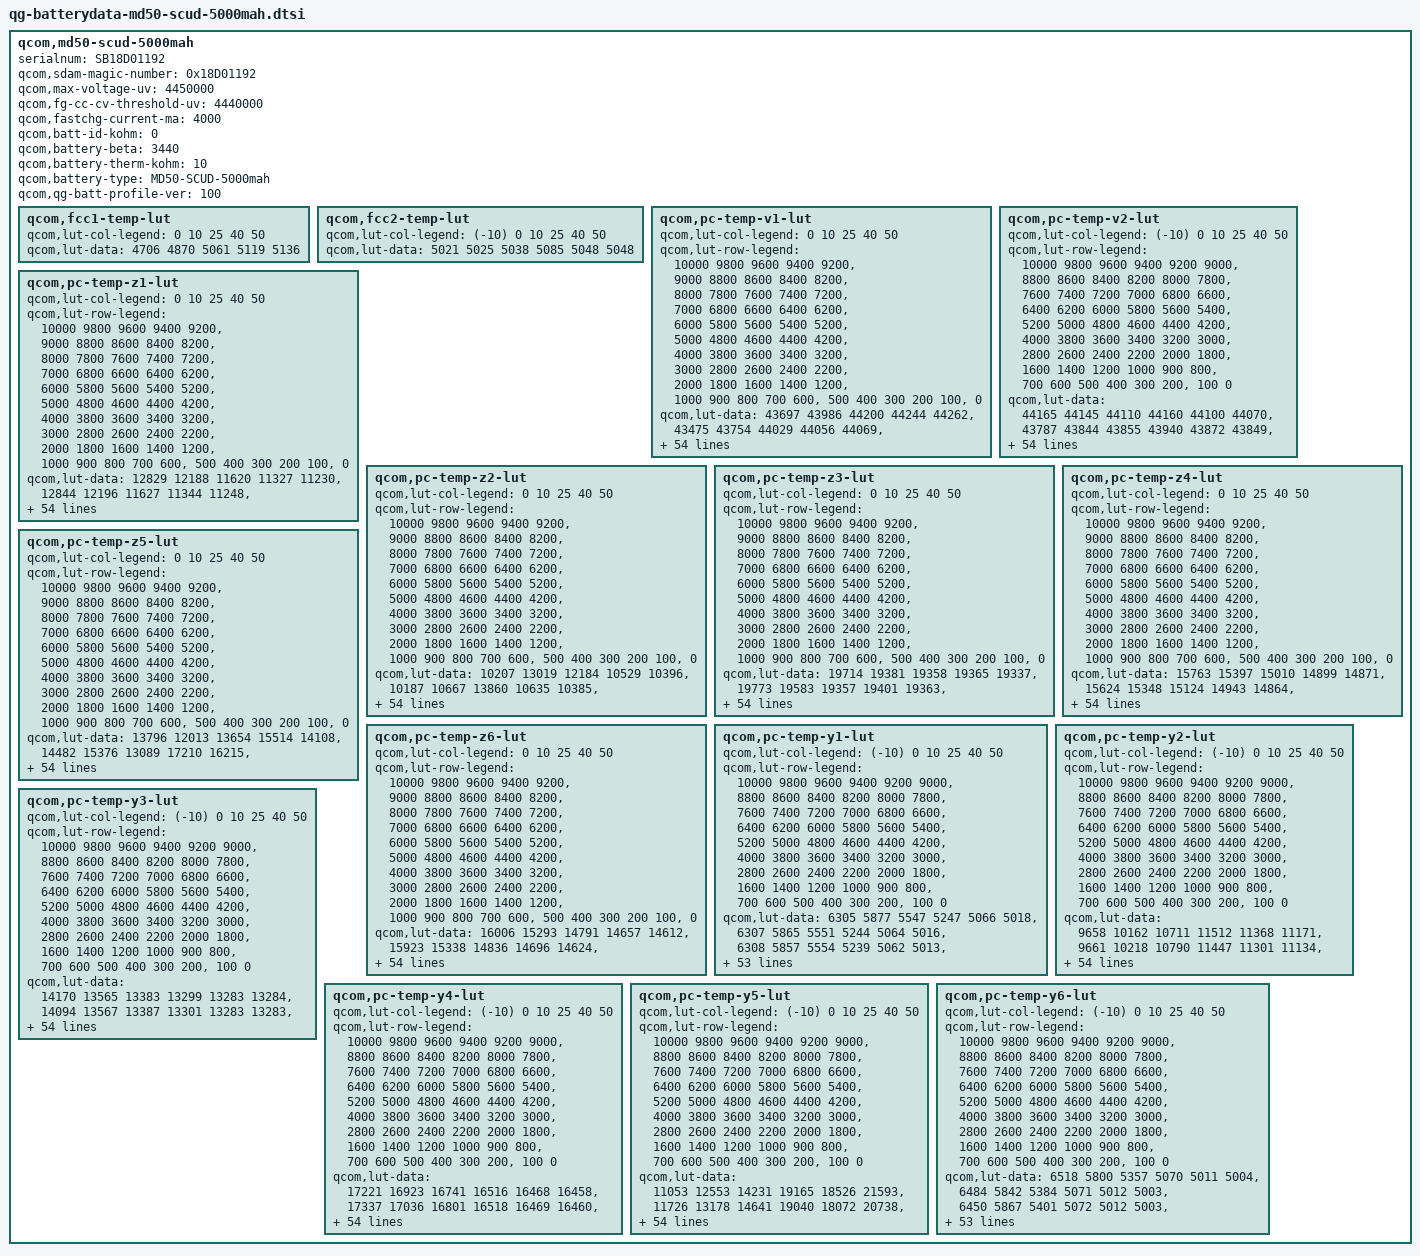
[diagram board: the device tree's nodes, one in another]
qcom,md50-scud-5000mah {
    /* 5012248_Lenovo_Denver_5000mAH_PM7250B_averaged_MasterSlave_Jan4th2021 */
    serialnum = "SB18D01192";
    qcom,sdam-magic-number = <0x18D01192>;
    qcom,max-voltage-uv = <4450000>;
    qcom,fg-cc-cv-threshold-uv = <4440000>;
    qcom,fastchg-current-ma = <4000>;
    qcom,batt-id-kohm = <0>;
    qcom,battery-beta = <3440>;
    qcom,battery-therm-kohm = <10>;
    qcom,battery-type = "MD50-SCUD-5000mah";
    qcom,qg-batt-profile-ver = <100>;

	qcom,fcc1-temp-lut {
		qcom,lut-col-legend = <0 10 25 40 50>;
		qcom,lut-data = <4706 4870 5061 5119 5136>;
	};

	qcom,fcc2-temp-lut {
		qcom,lut-col-legend = <(-10) 0 10 25 40 50>;
		qcom,lut-data = <5021 5025 5038 5085 5048 5048>;
	};

	qcom,pc-temp-v1-lut {
		qcom,lut-col-legend = <0 10 25 40 50>;
		qcom,lut-row-legend = <10000 9800 9600 9400 9200>,
			<9000 8800 8600 8400 8200>,
			<8000 7800 7600 7400 7200>,
			<7000 6800 6600 6400 6200>,
			<6000 5800 5600 5400 5200>,
			<5000 4800 4600 4400 4200>,
			<4000 3800 3600 3400 3200>,
			<3000 2800 2600 2400 2200>,
			<2000 1800 1600 1400 1200>,
			<1000 900 800 700 600>,
			<500 400 300 200 100>,
			<0>;
		qcom,lut-data = <43697 43986 44200 44244 44262>,
			<43475 43754 44029 44056 44069>,
			<43251 43531 43824 43871 43877>,
			<43024 43314 43608 43687 43687>,
			<42795 43092 43389 43484 43487>,
			<42567 42859 43163 43255 43272>,
			<42337 42625 42931 43019 43047>,
			<42111 42392 42691 42781 42815>,
			<41890 42161 42449 42540 42576>,
			<41676 41934 42208 42301 42337>,
			<41465 41710 41970 42067 42099>,
			<41258 41491 41737 41832 41862>,
			<41055 41279 41510 41595 41627>,
			<40852 41077 41290 41361 41394>,
			<40640 40876 41081 41138 41168>,
			<40432 40667 40877 40923 40948>,
			<40241 40457 40667 40716 40736>,
			<40064 40263 40451 40516 40535>,
			<39896 40083 40248 40322 40341>,
			<39738 39907 40076 40135 40152>,
			<39587 39732 39903 39954 39970>,
			<39435 39559 39669 39737 39762>,
			<39279 39366 39367 39440 39483>,
			<39123 39112 39128 39170 39216>,
			<38975 38879 38970 39010 39047>,
			<38829 38756 38845 38890 38920>,
			<38707 38675 38741 38780 38803>,
			<38620 38607 38655 38678 38696>,
			<38550 38542 38573 38585 38596>,
			<38491 38483 38492 38494 38501>,
			<38442 38428 38418 38409 38412>,
			<38399 38376 38350 38331 38327>,
			<38359 38327 38288 38259 38246>,
			<38324 38283 38228 38189 38168>,
			<38289 38243 38171 38118 38093>,
			<38254 38202 38117 38050 38020>,
			<38218 38162 38068 37988 37951>,
			<38173 38116 38023 37933 37887>,
			<38112 38046 37961 37865 37811>,
			<38036 37951 37866 37770 37709>,
			<37941 37844 37754 37658 37593>,
			<37816 37716 37635 37540 37470>,
			<37669 37572 37500 37408 37336>,
			<37497 37400 37334 37248 37177>,
			<37339 37261 37183 37103 37037>,
			<37242 37183 37094 37013 36955>,
			<37204 37160 37069 36993 36930>,
			<37174 37130 37054 36976 36915>,
			<37145 37101 37034 36961 36897>,
			<37087 37055 36996 36918 36846>,
			<36887 36857 36794 36692 36604>,
			<36428 36405 36361 36257 36167>,
			<35841 35818 35781 35678 35589>,
			<35046 35020 34990 34888 34805>,
			<33784 33769 33762 33667 33582>,
			<30000 30000 30000 30000 30000>;
	};

	qcom,pc-temp-v2-lut {
		qcom,lut-col-legend = <(-10) 0 10 25 40 50>;
		qcom,lut-row-legend = <10000 9800 9600 9400 9200 9000>,
			<8800 8600 8400 8200 8000 7800>,
			<7600 7400 7200 7000 6800 6600>,
			<6400 6200 6000 5800 5600 5400>,
			<5200 5000 4800 4600 4400 4200>,
			<4000 3800 3600 3400 3200 3000>,
			<2800 2600 2400 2200 2000 1800>,
			<1600 1400 1200 1000 900 800>,
			<700 600 500 400 300 200>,
			<100 0>;
		qcom,lut-data = <44165 44145 44110 44160 44100 44070>,
			<43787 43844 43855 43940 43872 43849>,
			<43441 43561 43606 43721 43647 43629>,
			<43133 43297 43366 43504 43427 43413>,
			<42857 43055 43135 43290 43212 43199>,
			<42595 42810 42899 43070 42992 42980>,
			<42339 42544 42652 42835 42760 42750>,
			<42090 42276 42401 42594 42522 42514>,
			<41833 42033 42154 42354 42286 42279>,
			<41562 41811 41910 42112 42047 42041>,
			<41347 41583 41670 41875 41812 41807>,
			<41221 41331 41428 41641 41579 41575>,
			<41110 41081 41193 41412 41351 41347>,
			<40918 40878 40976 41186 41128 41123>,
			<40610 40711 40773 40963 40910 40904>,
			<40288 40529 40574 40748 40698 40693>,
			<39974 40301 40378 40540 40492 40489>,
			<39670 40051 40179 40337 40291 40291>,
			<39412 39804 39961 40141 40102 40103>,
			<39187 39555 39724 39949 39923 39923>,
			<38981 39311 39489 39732 39721 39720>,
			<38773 39071 39251 39473 39463 39467>,
			<38592 38840 39026 39226 39208 39216>,
			<38470 38622 38842 39029 39016 39025>,
			<38380 38407 38682 38856 38855 38864>,
			<38303 38263 38536 38709 38716 38723>,
			<38235 38184 38402 38584 38593 38599>,
			<38172 38125 38279 38473 38485 38488>,
			<38109 38068 38157 38370 38384 38386>,
			<38046 38017 38041 38274 38290 38290>,
			<37986 37969 37961 38185 38204 38202>,
			<37928 37924 37912 38101 38126 38121>,
			<37871 37880 37872 38024 38051 38043>,
			<37811 37833 37825 37955 37974 37965>,
			<37750 37785 37779 37889 37897 37886>,
			<37687 37733 37730 37819 37811 37793>,
			<37621 37677 37680 37745 37713 37674>,
			<37551 37616 37624 37667 37613 37555>,
			<37471 37542 37551 37583 37519 37456>,
			<37381 37455 37463 37494 37428 37364>,
			<37287 37356 37361 37401 37331 37266>,
			<37187 37241 37240 37298 37229 37164>,
			<37087 37112 37108 37165 37104 37039>,
			<36994 36967 36970 37018 36957 36892>,
			<36915 36843 36848 36902 36856 36800>,
			<36833 36765 36749 36859 36827 36774>,
			<36787 36734 36706 36846 36818 36763>,
			<36737 36705 36660 36830 36803 36747>,
			<36669 36661 36602 36799 36776 36713>,
			<36555 36578 36506 36717 36683 36583>,
			<36319 36350 36276 36436 36346 36200>,
			<35898 35887 35827 35931 35833 35670>,
			<35268 35226 35186 35266 35161 34970>,
			<34356 34290 34281 34338 34209 33967>,
			<32823 32751 32749 32980 32675 32489>,
			<28965 28440 27863 27737 28090 28589>;
	};

	qcom,pc-temp-z1-lut {
		qcom,lut-col-legend = <0 10 25 40 50>;
		qcom,lut-row-legend = <10000 9800 9600 9400 9200>,
			<9000 8800 8600 8400 8200>,
			<8000 7800 7600 7400 7200>,
			<7000 6800 6600 6400 6200>,
			<6000 5800 5600 5400 5200>,
			<5000 4800 4600 4400 4200>,
			<4000 3800 3600 3400 3200>,
			<3000 2800 2600 2400 2200>,
			<2000 1800 1600 1400 1200>,
			<1000 900 800 700 600>,
			<500 400 300 200 100>,
			<0>;
		qcom,lut-data = <12829 12188 11620 11327 11230>,
			<12844 12196 11627 11344 11248>,
			<12852 12203 11637 11344 11248>,
			<12852 12212 11645 11342 11248>,
			<12851 12216 11639 11339 11247>,
			<12847 12215 11625 11333 11244>,
			<12827 12212 11616 11327 11240>,
			<12803 12206 11610 11322 11237>,
			<12794 12194 11604 11318 11235>,
			<12796 12180 11593 11314 11235>,
			<12796 12157 11581 11312 11236>,
			<12779 12134 11577 11310 11237>,
			<12745 12128 11575 11308 11236>,
			<12723 12128 11573 11307 11236>,
			<12713 12128 11570 11307 11235>,
			<12706 12122 11566 11307 11234>,
			<12701 12111 11563 11307 11234>,
			<12689 12102 11560 11305 11234>,
			<12679 12092 11559 11304 11235>,
			<12675 12086 11560 11305 11235>,
			<12672 12090 11562 11305 11236>,
			<12666 12101 11563 11306 11237>,
			<12654 12105 11564 11305 11236>,
			<12639 12099 11564 11305 11236>,
			<12631 12092 11567 11306 11236>,
			<12623 12092 11570 11308 11236>,
			<12616 12094 11570 11309 11237>,
			<12610 12096 11571 11311 11239>,
			<12604 12099 11572 11313 11242>,
			<12601 12103 11576 11317 11245>,
			<12599 12104 11581 11321 11248>,
			<12597 12105 11585 11326 11252>,
			<12598 12106 11589 11330 11256>,
			<12603 12108 11593 11334 11260>,
			<12608 12109 11598 11340 11264>,
			<12616 12113 11604 11346 11269>,
			<12632 12123 11607 11350 11272>,
			<12639 12134 11610 11353 11275>,
			<12651 12143 11616 11356 11278>,
			<12668 12153 11627 11359 11281>,
			<12685 12162 11637 11362 11284>,
			<12715 12170 11643 11366 11286>,
			<12745 12184 11647 11371 11288>,
			<12771 12216 11648 11376 11290>,
			<12725 12210 11654 11381 11294>,
			<12736 12203 11663 11386 11297>,
			<12719 12199 11662 11388 11297>,
			<12716 12213 11664 11386 11298>,
			<12734 12198 11652 11390 11301>,
			<12727 12214 11669 11392 11304>,
			<12754 12225 11669 11398 11308>,
			<12777 12240 11685 11404 11313>,
			<12760 12232 11692 11414 11322>,
			<12800 12271 11710 11427 11335>,
			<12800 12271 11710 11427 11335>,
			<12800 12271 11710 11427 11335>;
	};

	qcom,pc-temp-z2-lut {
		qcom,lut-col-legend = <0 10 25 40 50>;
		qcom,lut-row-legend = <10000 9800 9600 9400 9200>,
			<9000 8800 8600 8400 8200>,
			<8000 7800 7600 7400 7200>,
			<7000 6800 6600 6400 6200>,
			<6000 5800 5600 5400 5200>,
			<5000 4800 4600 4400 4200>,
			<4000 3800 3600 3400 3200>,
			<3000 2800 2600 2400 2200>,
			<2000 1800 1600 1400 1200>,
			<1000 900 800 700 600>,
			<500 400 300 200 100>,
			<0>;
		qcom,lut-data = <10207 13019 12184 10529 10396>,
			<10187 10667 13860 10635 10385>,
			<10166 10426 12145 11080 10591>,
			<10143 10400 10677 11779 10582>,
			<10118 10375 10577 11902 10568>,
			<10098 10340 10538 11158 10525>,
			<10080 10308 10504 10529 10469>,
			<10066 10286 10471 10460 10430>,
			<10062 10270 10444 10425 10396>,
			<10061 10258 10418 10503 10361>,
			<10061 10249 10398 10976 10314>,
			<10062 10243 10395 11274 10286>,
			<10064 10243 10400 10942 10305>,
			<10065 10252 10411 10472 10344>,
			<10059 10262 10656 10506 10364>,
			<10050 10272 11016 10880 10378>,
			<10051 10284 11011 11069 10383>,
			<10065 10301 10704 11337 10338>,
			<10083 10332 10528 11639 10278>,
			<10101 10361 10540 11433 10293>,
			<10121 10378 10564 10805 10399>,
			<10141 10392 10600 10579 10511>,
			<10160 10398 10659 10674 10651>,
			<10180 10400 10684 10761 10758>,
			<10199 10401 10643 10693 10674>,
			<10219 10401 10595 10539 10438>,
			<10239 10401 10593 10501 10360>,
			<10259 10401 10605 10530 10394>,
			<10280 10407 10615 10560 10428>,
			<10297 10417 10630 10599 10436>,
			<10309 10428 10643 10649 10442>,
			<10320 10441 10642 10658 10469>,
			<10334 10454 10639 10658 10568>,
			<10348 10464 10638 10658 10631>,
			<10363 10473 10649 10658 10619>,
			<10380 10484 10665 10660 10601>,
			<10398 10494 10678 10679 10604>,
			<10407 10507 10692 10735 10637>,
			<10368 10525 10714 10787 10680>,
			<10310 10549 10755 10835 10755>,
			<10248 10572 10792 10867 10822>,
			<10112 10592 10805 10867 10833>,
			<10026 10623 10815 10863 10829>,
			<9965 10688 10838 10866 10817>,
			<9722 11016 10982 10900 10763>,
			<9516 10899 11105 10940 10682>,
			<9514 10691 11085 10786 10650>,
			<9515 10650 11063 10764 10653>,
			<9517 10661 11055 10803 10696>,
			<9536 10595 11122 10948 10852>,
			<9556 10635 11231 10880 10707>,
			<9436 10499 11215 10715 10423>,
			<9384 10361 11129 10585 10333>,
			<9344 10237 11079 10469 10292>,
			<9344 10237 11079 10469 10292>,
			<9344 10237 11079 10469 10292>;
	};

	qcom,pc-temp-z3-lut {
		qcom,lut-col-legend = <0 10 25 40 50>;
		qcom,lut-row-legend = <10000 9800 9600 9400 9200>,
			<9000 8800 8600 8400 8200>,
			<8000 7800 7600 7400 7200>,
			<7000 6800 6600 6400 6200>,
			<6000 5800 5600 5400 5200>,
			<5000 4800 4600 4400 4200>,
			<4000 3800 3600 3400 3200>,
			<3000 2800 2600 2400 2200>,
			<2000 1800 1600 1400 1200>,
			<1000 900 800 700 600>,
			<500 400 300 200 100>,
			<0>;
		qcom,lut-data = <19714 19381 19358 19365 19337>,
			<19773 19583 19357 19401 19363>,
			<19811 19626 19428 19417 19396>,
			<19822 19643 19484 19424 19404>,
			<19828 19649 19494 19431 19409>,
			<19833 19651 19500 19440 19416>,
			<19840 19651 19501 19446 19421>,
			<19846 19649 19500 19446 19421>,
			<19845 19644 19498 19446 19421>,
			<19830 19640 19496 19449 19420>,
			<19813 19638 19493 19468 19415>,
			<19806 19634 19486 19479 19409>,
			<19799 19630 19471 19456 19405>,
			<19798 19624 19463 19421 19400>,
			<19813 19618 19476 19413 19396>,
			<19833 19616 19497 19417 19392>,
			<19837 19613 19494 19420 19388>,
			<19834 19611 19462 19422 19377>,
			<19831 19605 19442 19422 19367>,
			<19831 19602 19438 19411 19366>,
			<19830 19603 19437 19391 19366>,
			<19830 19608 19442 19385 19367>,
			<19834 19614 19464 19396 19375>,
			<19839 19625 19475 19407 19382>,
			<19839 19634 19467 19400 19376>,
			<19836 19633 19455 19384 19360>,
			<19830 19624 19447 19375 19351>,
			<19820 19616 19440 19371 19347>,
			<19805 19608 19438 19369 19345>,
			<19791 19600 19440 19369 19346>,
			<19779 19596 19442 19371 19349>,
			<19767 19595 19444 19375 19354>,
			<19756 19593 19446 19381 19370>,
			<19745 19590 19448 19386 19379>,
			<19735 19586 19449 19389 19377>,
			<19726 19583 19450 19392 19373>,
			<19717 19580 19447 19391 19369>,
			<19701 19577 19441 19384 19364>,
			<19623 19573 19437 19380 19360>,
			<19538 19566 19435 19378 19357>,
			<19490 19559 19434 19376 19356>,
			<19388 19552 19429 19374 19357>,
			<19357 19543 19423 19371 19362>,
			<19347 19527 19418 19369 19362>,
			<19314 19468 19404 19364 19360>,
			<19285 19377 19384 19355 19341>,
			<19284 19311 19384 19345 19338>,
			<19284 19304 19379 19343 19330>,
			<19282 19299 19377 19336 19326>,
			<19276 19296 19372 19326 19319>,
			<19274 19301 19364 19336 19337>,
			<19287 19301 19365 19367 19361>,
			<19291 19301 19366 19367 19363>,
			<19296 19301 19336 19362 19351>,
			<19296 19301 19336 19362 19351>,
			<19296 19301 19336 19362 19351>;
	};

	qcom,pc-temp-z4-lut {
		qcom,lut-col-legend = <0 10 25 40 50>;
		qcom,lut-row-legend = <10000 9800 9600 9400 9200>,
			<9000 8800 8600 8400 8200>,
			<8000 7800 7600 7400 7200>,
			<7000 6800 6600 6400 6200>,
			<6000 5800 5600 5400 5200>,
			<5000 4800 4600 4400 4200>,
			<4000 3800 3600 3400 3200>,
			<3000 2800 2600 2400 2200>,
			<2000 1800 1600 1400 1200>,
			<1000 900 800 700 600>,
			<500 400 300 200 100>,
			<0>;
		qcom,lut-data = <15763 15397 15010 14899 14871>,
			<15624 15348 15124 14943 14864>,
			<15501 15271 15070 14940 14898>,
			<15395 15166 15003 14873 14867>,
			<15301 15079 14952 14835 14838>,
			<15220 15015 14905 14820 14814>,
			<15147 14962 14866 14806 14792>,
			<15086 14920 14833 14788 14773>,
			<15047 14887 14805 14767 14756>,
			<15020 14859 14780 14735 14741>,
			<14998 14835 14759 14680 14729>,
			<14974 14814 14745 14650 14717>,
			<14952 14796 14737 14668 14707>,
			<14929 14779 14727 14693 14697>,
			<14899 14764 14688 14690 14690>,
			<14871 14753 14641 14666 14683>,
			<14853 14744 14642 14652 14680>,
			<14841 14736 14678 14639 14679>,
			<14829 14729 14698 14624 14679>,
			<14813 14724 14694 14630 14677>,
			<14797 14722 14689 14650 14672>,
			<14786 14722 14700 14678 14671>,
			<14779 14723 14744 14728 14712>,
			<14775 14761 14777 14771 14764>,
			<14776 14804 14795 14788 14784>,
			<14785 14808 14806 14799 14798>,
			<14792 14801 14804 14800 14800>,
			<14790 14793 14795 14792 14793>,
			<14784 14784 14784 14782 14782>,
			<14777 14774 14769 14768 14769>,
			<14770 14763 14753 14752 14753>,
			<14763 14750 14737 14734 14732>,
			<14756 14738 14721 14713 14701>,
			<14748 14729 14710 14696 14681>,
			<14741 14720 14700 14685 14677>,
			<14733 14714 14694 14678 14675>,
			<14725 14707 14693 14677 14674>,
			<14725 14704 14693 14678 14675>,
			<14797 14705 14693 14679 14676>,
			<14877 14706 14700 14688 14686>,
			<14918 14707 14706 14697 14697>,
			<15018 14702 14704 14698 14694>,
			<15031 14697 14701 14696 14686>,
			<15000 14692 14698 14696 14686>,
			<14914 14680 14683 14688 14682>,
			<14925 14740 14663 14665 14669>,
			<14922 14806 14656 14666 14666>,
			<14917 14810 14647 14655 14658>,
			<14914 14810 14638 14645 14641>,
			<14912 14811 14640 14646 14639>,
			<14910 14807 14661 14662 14652>,
			<14919 14818 14674 14647 14646>,
			<14926 14822 14675 14651 14649>,
			<14939 14829 14712 14661 14664>,
			<14939 14829 14712 14661 14664>,
			<14939 14829 14712 14661 14664>;
	};

	qcom,pc-temp-z5-lut {
		qcom,lut-col-legend = <0 10 25 40 50>;
		qcom,lut-row-legend = <10000 9800 9600 9400 9200>,
			<9000 8800 8600 8400 8200>,
			<8000 7800 7600 7400 7200>,
			<7000 6800 6600 6400 6200>,
			<6000 5800 5600 5400 5200>,
			<5000 4800 4600 4400 4200>,
			<4000 3800 3600 3400 3200>,
			<3000 2800 2600 2400 2200>,
			<2000 1800 1600 1400 1200>,
			<1000 900 800 700 600>,
			<500 400 300 200 100>,
			<0>;
		qcom,lut-data = <13796 12013 13654 15514 14108>,
			<14482 15376 13089 17210 16215>,
			<15001 16499 15171 17301 17998>,
			<15297 17055 17070 17262 18462>,
			<15494 17504 17650 17379 18850>,
			<15744 17966 18014 18612 19420>,
			<16255 18361 18438 19944 20012>,
			<16758 18680 18915 20493 20512>,
			<16832 19056 19457 20949 20957>,
			<16658 19458 20300 23276 21171>,
			<16512 19985 21154 32246 21167>,
			<16537 20642 21280 37725 21308>,
			<16659 21255 21077 32499 22043>,
			<16872 21818 20956 24892 23220>,
			<18037 22507 30023 26046 24316>,
			<19763 23554 43712 35857 25512>,
			<20954 24947 43534 40727 26078>,
			<21761 26424 31786 44638 25072>,
			<22717 27891 25038 48166 23662>,
			<24227 29771 25476 43256 24111>,
			<26411 32914 26612 33557 27059>,
			<29390 37728 33090 30766 30435>,
			<34956 43200 52809 39925 35306>,
			<41436 51205 62296 48302 39155>,
			<46239 57714 51612 42768 35733>,
			<50714 56062 36901 29574 25597>,
			<53118 47110 30609 23532 20540>,
			<52141 39969 26571 21127 18851>,
			<49519 36356 25164 20027 18018>,
			<47004 33940 25054 19862 17838>,
			<44484 33738 25188 19823 17778>,
			<42292 34753 25938 20164 18456>,
			<41029 36114 27943 21926 22683>,
			<39611 37611 30643 24417 26708>,
			<38809 39430 35833 29422 29117>,
			<38621 41416 39856 34360 30817>,
			<38264 44028 39743 34833 30946>,
			<37865 45851 38903 34393 30535>,
			<33367 46085 38275 33729 29907>,
			<28379 46015 37656 32353 28313>,
			<24691 45670 36725 30408 26636>,
			<14537 44216 34202 27659 25995>,
			<12224 42622 31267 24895 25609>,
			<12276 41505 30531 24678 25837>,
			<12637 35568 32418 25152 25910>,
			<12081 21047 31790 26051 22104>,
			<12063 13245 32729 22695 21084>,
			<12035 12981 31772 23743 20137>,
			<11993 12841 32869 23256 22408>,
			<11987 12771 30841 21204 21240>,
			<12045 13022 23772 20824 23156>,
			<12096 12885 20340 25746 26258>,
			<12016 12731 19676 24135 24359>,
			<11913 12556 15240 20338 18409>,
			<11913 12556 15240 20338 18409>,
			<11913 12556 15240 20338 18409>;
	};

	qcom,pc-temp-z6-lut {
		qcom,lut-col-legend = <0 10 25 40 50>;
		qcom,lut-row-legend = <10000 9800 9600 9400 9200>,
			<9000 8800 8600 8400 8200>,
			<8000 7800 7600 7400 7200>,
			<7000 6800 6600 6400 6200>,
			<6000 5800 5600 5400 5200>,
			<5000 4800 4600 4400 4200>,
			<4000 3800 3600 3400 3200>,
			<3000 2800 2600 2400 2200>,
			<2000 1800 1600 1400 1200>,
			<1000 900 800 700 600>,
			<500 400 300 200 100>,
			<0>;
		qcom,lut-data = <16006 15293 14791 14657 14612>,
			<15923 15338 14836 14696 14624>,
			<15844 15321 14838 14701 14654>,
			<15769 15255 14838 14680 14646>,
			<15696 15194 14827 14668 14639>,
			<15634 15150 14800 14663 14632>,
			<15582 15110 14778 14658 14625>,
			<15536 15077 14760 14650 14618>,
			<15496 15048 14744 14640 14610>,
			<15460 15023 14729 14630 14603>,
			<15428 15003 14716 14620 14596>,
			<15400 14984 14703 14610 14588>,
			<15374 14967 14692 14602 14581>,
			<15353 14949 14682 14595 14574>,
			<15337 14934 14672 14588 14568>,
			<15324 14923 14663 14581 14563>,
			<15310 14913 14658 14575 14558>,
			<15297 14905 14655 14569 14552>,
			<15284 14898 14653 14564 14546>,
			<15272 14893 14649 14562 14543>,
			<15260 14894 14647 14561 14542>,
			<15252 14897 14655 14563 14542>,
			<15248 14902 14687 14591 14565>,
			<15246 14925 14704 14617 14590>,
			<15243 14948 14706 14617 14592>,
			<15241 14949 14707 14615 14590>,
			<15238 14943 14705 14613 14588>,
			<15231 14936 14698 14608 14584>,
			<15219 14929 14692 14602 14579>,
			<15208 14922 14687 14597 14574>,
			<15198 14916 14682 14592 14569>,
			<15189 14910 14678 14587 14564>,
			<15181 14906 14673 14582 14560>,
			<15174 14901 14670 14579 14557>,
			<15168 14898 14668 14577 14554>,
			<15162 14896 14667 14576 14552>,
			<15158 14895 14665 14574 14549>,
			<15156 14894 14663 14571 14546>,
			<15156 14896 14663 14570 14545>,
			<15157 14899 14666 14573 14548>,
			<15157 14900 14669 14576 14552>,
			<15159 14900 14668 14576 14551>,
			<15157 14900 14666 14574 14551>,
			<15152 14897 14664 14574 14551>,
			<15111 14871 14655 14568 14548>,
			<15102 14855 14639 14555 14533>,
			<15101 14850 14636 14550 14530>,
			<15099 14849 14629 14544 14523>,
			<15100 14848 14625 14536 14514>,
			<15104 14850 14625 14532 14509>,
			<15113 14857 14633 14545 14524>,
			<15129 14869 14642 14557 14537>,
			<15146 14879 14647 14561 14542>,
			<15172 14895 14653 14566 14545>,
			<15172 14895 14653 14566 14545>,
			<15172 14895 14653 14566 14545>;
	};

	qcom,pc-temp-y1-lut {
		qcom,lut-col-legend = <(-10) 0 10 25 40 50>;
		qcom,lut-row-legend = <10000 9800 9600 9400 9200 9000>,
			<8800 8600 8400 8200 8000 7800>,
			<7600 7400 7200 7000 6800 6600>,
			<6400 6200 6000 5800 5600 5400>,
			<5200 5000 4800 4600 4400 4200>,
			<4000 3800 3600 3400 3200 3000>,
			<2800 2600 2400 2200 2000 1800>,
			<1600 1400 1200 1000 900 800>,
			<700 600 500 400 300 200>,
			<100 0>;
		qcom,lut-data = <6305 5877 5547 5247 5066 5018>,
			<6307 5865 5551 5244 5064 5016>,
			<6308 5857 5554 5239 5062 5013>,
			<6309 5852 5555 5235 5060 5010>,
			<6310 5850 5555 5231 5059 5007>,
			<6310 5850 5555 5229 5058 5005>,
			<6311 5853 5554 5227 5057 5002>,
			<6312 5859 5552 5226 5057 5000>,
			<6313 5861 5551 5224 5055 4998>,
			<6318 5862 5551 5221 5053 4996>,
			<6322 5863 5550 5219 5051 4995>,
			<6326 5865 5550 5218 5050 4994>,
			<6331 5868 5549 5217 5049 4992>,
			<6334 5869 5550 5216 5048 4991>,
			<6343 5870 5551 5215 5047 4990>,
			<6348 5871 5551 5214 5047 4990>,
			<6346 5871 5552 5213 5046 4990>,
			<6343 5871 5553 5212 5045 4989>,
			<6341 5872 5553 5213 5045 4990>,
			<6336 5875 5553 5216 5046 4990>,
			<6333 5877 5553 5217 5046 4990>,
			<6333 5878 5553 5216 5047 4990>,
			<6333 5878 5554 5216 5047 4990>,
			<6333 5878 5555 5218 5047 4990>,
			<6331 5876 5555 5220 5048 4991>,
			<6329 5873 5556 5221 5049 4992>,
			<6329 5871 5556 5222 5050 4993>,
			<6329 5869 5557 5223 5051 4993>,
			<6328 5868 5558 5225 5052 4994>,
			<6326 5868 5560 5227 5054 4997>,
			<6324 5867 5561 5229 5056 4998>,
			<6322 5866 5559 5231 5058 5000>,
			<6320 5864 5558 5233 5060 5002>,
			<6318 5861 5558 5235 5062 5003>,
			<6315 5856 5560 5237 5064 5004>,
			<6314 5854 5561 5239 5065 5005>,
			<6312 5854 5558 5240 5066 5007>,
			<6311 5854 5556 5241 5067 5008>,
			<6309 5851 5555 5242 5068 5009>,
			<6305 5846 5555 5242 5069 5009>,
			<6304 5844 5554 5243 5071 5010>,
			<6299 5845 5554 5244 5073 5011>,
			<6296 5846 5554 5247 5074 5012>,
			<6300 5843 5557 5250 5075 5015>,
			<6309 5850 5560 5253 5079 5018>,
			<6324 5868 5566 5256 5081 5020>,
			<6335 5870 5568 5258 5082 5020>,
			<6338 5875 5570 5258 5082 5020>,
			<6338 5874 5573 5259 5081 5021>,
			<6341 5871 5574 5262 5082 5022>,
			<6351 5870 5581 5261 5085 5024>,
			<6341 5876 5586 5267 5087 5029>,
			<6383 5892 5596 5279 5096 5035>,
			<6537 5924 5616 5294 5105 5044>,
			<6537 5924 5616 5294 5105 5044>,
			<6537 5924 5616 5294 5105 5044>;
	};

	qcom,pc-temp-y2-lut {
		qcom,lut-col-legend = <(-10) 0 10 25 40 50>;
		qcom,lut-row-legend = <10000 9800 9600 9400 9200 9000>,
			<8800 8600 8400 8200 8000 7800>,
			<7600 7400 7200 7000 6800 6600>,
			<6400 6200 6000 5800 5600 5400>,
			<5200 5000 4800 4600 4400 4200>,
			<4000 3800 3600 3400 3200 3000>,
			<2800 2600 2400 2200 2000 1800>,
			<1600 1400 1200 1000 900 800>,
			<700 600 500 400 300 200>,
			<100 0>;
		qcom,lut-data = <9658 10162 10711 11512 11368 11171>,
			<9661 10218 10790 11447 11301 11134>,
			<9664 10305 10851 11385 11219 11096>,
			<9668 10399 10893 11327 11138 11059>,
			<9670 10473 10917 11276 11073 11021>,
			<9672 10502 10925 11235 11040 10984>,
			<9674 10495 10905 11199 11032 10941>,
			<9676 10484 10876 11171 11031 10904>,
			<9676 10515 10867 11155 11033 10889>,
			<9676 10668 10864 11145 11041 10879>,
			<9675 10757 10863 11134 11045 10877>,
			<9677 10737 10870 11115 11042 10918>,
			<9680 10708 10887 11101 11041 10967>,
			<9680 10722 10925 11104 11053 10962>,
			<9680 10807 11015 11117 11079 10921>,
			<9679 10881 11090 11136 11103 10902>,
			<9676 10926 11135 11172 11117 10959>,
			<9673 10956 11170 11223 11134 11049>,
			<9671 10958 11201 11286 11179 11116>,
			<9670 10946 11231 11360 11267 11178>,
			<9669 10916 11242 11400 11333 11224>,
			<9668 10418 11235 11416 11375 11266>,
			<9667 9797 11225 11432 11404 11296>,
			<9667 9702 11218 11464 11413 11299>,
			<9666 9691 11213 11505 11417 11290>,
			<9665 9684 11204 11532 11424 11293>,
			<9665 9680 11170 11548 11449 11319>,
			<9665 9678 11128 11567 11478 11357>,
			<9665 9675 11102 11602 11539 11427>,
			<9664 9673 11080 11643 11658 11537>,
			<9664 9670 11051 11666 11718 11603>,
			<9663 9668 11003 11683 11755 11638>,
			<9663 9666 10925 11690 11781 11665>,
			<9663 9665 10694 11682 11787 11711>,
			<9663 9664 10251 11669 11790 11777>,
			<9663 9663 9987 11661 11775 11789>,
			<9663 9663 9863 11655 11708 11722>,
			<9662 9662 9785 11644 11646 11649>,
			<9662 9662 9741 11609 11622 11570>,
			<9662 9662 9711 11562 11606 11456>,
			<9662 9661 9694 11529 11606 11437>,
			<9662 9661 9684 11501 11626 11502>,
			<9662 9661 9676 11476 11625 11502>,
			<9661 9661 9671 11436 11572 11365>,
			<9661 9660 9667 11395 11401 11211>,
			<9660 9659 9666 11352 11322 11129>,
			<9660 9659 9665 11349 11316 11149>,
			<9659 9659 9664 11321 11312 11156>,
			<9659 9659 9662 11307 11318 11195>,
			<9658 9658 9661 11290 11341 11160>,
			<9657 9658 9660 11263 11285 11007>,
			<9656 9657 9659 11189 11182 10952>,
			<9654 9656 9658 11079 11102 10904>,
			<9652 9654 9657 10933 10975 10753>,
			<9652 9654 9657 10933 10975 10753>,
			<9652 9654 9657 10933 10975 10753>;
	};

	qcom,pc-temp-y3-lut {
		qcom,lut-col-legend = <(-10) 0 10 25 40 50>;
		qcom,lut-row-legend = <10000 9800 9600 9400 9200 9000>,
			<8800 8600 8400 8200 8000 7800>,
			<7600 7400 7200 7000 6800 6600>,
			<6400 6200 6000 5800 5600 5400>,
			<5200 5000 4800 4600 4400 4200>,
			<4000 3800 3600 3400 3200 3000>,
			<2800 2600 2400 2200 2000 1800>,
			<1600 1400 1200 1000 900 800>,
			<700 600 500 400 300 200>,
			<100 0>;
		qcom,lut-data = <14170 13565 13383 13299 13283 13284>,
			<14094 13567 13387 13301 13283 13283>,
			<14019 13567 13393 13303 13283 13282>,
			<13950 13566 13398 13305 13284 13282>,
			<13890 13565 13403 13307 13285 13282>,
			<13843 13563 13406 13308 13285 13282>,
			<13810 13558 13407 13308 13286 13283>,
			<13782 13552 13407 13308 13287 13284>,
			<13743 13554 13408 13308 13288 13285>,
			<13688 13566 13408 13308 13289 13286>,
			<13661 13572 13409 13309 13290 13287>,
			<13666 13529 13411 13311 13290 13288>,
			<13672 13470 13413 13314 13291 13288>,
			<13673 13462 13409 13314 13292 13288>,
			<13667 13469 13394 13313 13296 13288>,
			<13659 13473 13385 13312 13298 13288>,
			<13633 13466 13384 13313 13297 13290>,
			<13603 13452 13383 13314 13296 13293>,
			<13598 13438 13380 13314 13297 13294>,
			<13598 13420 13372 13314 13299 13295>,
			<13598 13412 13363 13313 13299 13295>,
			<13593 13422 13356 13309 13295 13291>,
			<13587 13434 13349 13305 13289 13286>,
			<13589 13428 13345 13301 13286 13283>,
			<13606 13401 13341 13298 13284 13281>,
			<13628 13388 13337 13296 13283 13281>,
			<13655 13398 13334 13294 13282 13280>,
			<13688 13416 13331 13294 13282 13280>,
			<13721 13438 13325 13294 13282 13280>,
			<13755 13468 13317 13296 13283 13280>,
			<13792 13501 13314 13296 13283 13280>,
			<13832 13541 13319 13295 13283 13280>,
			<13873 13583 13326 13295 13283 13279>,
			<13910 13625 13328 13295 13283 13280>,
			<13944 13668 13329 13295 13283 13281>,
			<13979 13710 13333 13295 13283 13281>,
			<14016 13752 13346 13295 13283 13280>,
			<14053 13794 13365 13295 13282 13279>,
			<14086 13837 13383 13294 13282 13279>,
			<14117 13880 13403 13293 13282 13279>,
			<14147 13920 13426 13294 13282 13280>,
			<14176 13956 13455 13296 13285 13282>,
			<14208 13993 13491 13295 13284 13282>,
			<14248 14037 13538 13294 13281 13278>,
			<14321 14087 13611 13296 13282 13281>,
			<14366 14107 13608 13297 13287 13286>,
			<14438 14162 13659 13301 13291 13290>,
			<14522 14222 13720 13307 13295 13292>,
			<14625 14289 13796 13312 13298 13294>,
			<14771 14365 13880 13315 13297 13291>,
			<14976 14459 13954 13312 13293 13287>,
			<15390 14622 14063 13312 13290 13288>,
			<16713 14895 14258 13319 13296 13295>,
			<20926 15613 14486 13331 13303 13301>,
			<20926 15613 14486 13331 13303 13301>,
			<20926 15613 14486 13331 13303 13301>;
	};

	qcom,pc-temp-y4-lut {
		qcom,lut-col-legend = <(-10) 0 10 25 40 50>;
		qcom,lut-row-legend = <10000 9800 9600 9400 9200 9000>,
			<8800 8600 8400 8200 8000 7800>,
			<7600 7400 7200 7000 6800 6600>,
			<6400 6200 6000 5800 5600 5400>,
			<5200 5000 4800 4600 4400 4200>,
			<4000 3800 3600 3400 3200 3000>,
			<2800 2600 2400 2200 2000 1800>,
			<1600 1400 1200 1000 900 800>,
			<700 600 500 400 300 200>,
			<100 0>;
		qcom,lut-data = <17221 16923 16741 16516 16468 16458>,
			<17337 17036 16801 16518 16469 16460>,
			<17442 17163 16862 16519 16470 16461>,
			<17528 17281 16917 16520 16471 16462>,
			<17586 17369 16957 16520 16471 16464>,
			<17607 17401 16971 16521 16472 16465>,
			<17580 17386 16961 16521 16473 16466>,
			<17540 17355 16943 16522 16474 16466>,
			<17534 17319 16930 16524 16475 16468>,
			<17541 17268 16920 16528 16478 16469>,
			<17550 17244 16910 16531 16482 16471>,
			<17576 17300 16897 16534 16487 16475>,
			<17606 17378 16887 16538 16492 16480>,
			<17579 17387 16901 16544 16496 16486>,
			<17428 17374 16963 16557 16499 16494>,
			<17276 17353 16996 16571 16504 16501>,
			<17171 17301 16997 16588 16514 16506>,
			<17078 17224 16995 16608 16530 16511>,
			<17001 17150 16980 16636 16549 16523>,
			<16936 17072 16929 16667 16573 16543>,
			<16882 16993 16870 16670 16581 16550>,
			<16829 16911 16802 16613 16547 16526>,
			<16791 16833 16738 16553 16504 16494>,
			<16788 16767 16702 16524 16486 16480>,
			<16793 16704 16678 16504 16474 16469>,
			<16796 16681 16654 16500 16471 16466>,
			<16795 16685 16629 16502 16475 16469>,
			<16795 16693 16604 16506 16480 16473>,
			<16797 16699 16578 16510 16487 16479>,
			<16805 16705 16551 16515 16495 16487>,
			<16811 16711 16542 16520 16505 16496>,
			<16814 16717 16551 16527 16518 16509>,
			<16818 16724 16568 16533 16528 16518>,
			<16822 16733 16595 16539 16528 16521>,
			<16828 16743 16637 16543 16528 16522>,
			<16831 16753 16669 16540 16526 16520>,
			<16834 16762 16691 16527 16507 16500>,
			<16835 16768 16708 16516 16490 16482>,
			<16833 16768 16720 16507 16484 16480>,
			<16827 16767 16729 16501 16481 16479>,
			<16820 16766 16730 16504 16481 16479>,
			<16813 16758 16723 16512 16483 16482>,
			<16810 16746 16721 16513 16482 16480>,
			<16822 16727 16723 16512 16471 16465>,
			<16825 16719 16732 16493 16461 16456>,
			<16818 16708 16728 16501 16471 16472>,
			<16834 16721 16769 16516 16488 16499>,
			<16855 16739 16813 16538 16518 16534>,
			<16883 16774 16870 16574 16556 16572>,
			<16902 16818 16937 16603 16570 16558>,
			<16901 16820 16965 16561 16486 16481>,
			<16906 16797 16963 16543 16480 16480>,
			<17120 16803 16976 16564 16488 16483>,
			<18668 16971 16989 16616 16513 16511>,
			<18668 16971 16989 16616 16513 16511>,
			<18668 16971 16989 16616 16513 16511>;
	};

	qcom,pc-temp-y5-lut {
		qcom,lut-col-legend = <(-10) 0 10 25 40 50>;
		qcom,lut-row-legend = <10000 9800 9600 9400 9200 9000>,
			<8800 8600 8400 8200 8000 7800>,
			<7600 7400 7200 7000 6800 6600>,
			<6400 6200 6000 5800 5600 5400>,
			<5200 5000 4800 4600 4400 4200>,
			<4000 3800 3600 3400 3200 3000>,
			<2800 2600 2400 2200 2000 1800>,
			<1600 1400 1200 1000 900 800>,
			<700 600 500 400 300 200>,
			<100 0>;
		qcom,lut-data = <11053 12553 14231 19165 18526 21593>,
			<11726 13178 14641 19040 18072 20738>,
			<12418 13816 15040 18833 17577 19700>,
			<13070 14417 15409 18580 17099 18659>,
			<13626 14926 15731 18320 16694 17795>,
			<14027 15291 15988 18085 16419 17289>,
			<14334 15486 16209 17556 16267 17065>,
			<14549 15658 16375 16857 16139 16904>,
			<14474 16196 16432 16337 15955 16737>,
			<13985 17541 16457 15786 15713 16574>,
			<13700 18268 16455 15463 15437 16365>,
			<15166 16864 16330 15517 15018 16033>,
			<17551 14911 16110 15601 14656 15617>,
			<18781 15036 15832 15247 14752 15124>,
			<19615 16962 15367 14529 15238 14512>,
			<19926 18545 15167 14160 15458 14271>,
			<18376 19237 16154 14033 14868 14543>,
			<16200 19761 17697 13971 14179 14903>,
			<15722 20313 18690 14260 14202 15029>,
			<15642 20889 19486 15199 14595 15104>,
			<15489 21120 20099 16503 15238 15308>,
			<14266 20924 20546 19035 17249 17079>,
			<12708 20455 20919 20792 19122 18899>,
			<12240 18776 21271 20430 19124 18990>,
			<12034 14428 21590 19569 18662 18833>,
			<11970 12254 21963 19026 18143 18590>,
			<12104 12153 22569 18579 17443 17681>,
			<12294 12106 23041 18352 16907 16802>,
			<12359 12131 21457 18879 16898 16633>,
			<12362 12259 16864 19783 17087 16551>,
			<12387 12430 15043 20072 17271 16460>,
			<12547 12721 15294 20138 17486 16235>,
			<12755 13022 15548 20250 17779 16059>,
			<12871 13182 15135 21102 18221 16766>,
			<12953 13311 14016 22225 18835 18429>,
			<13045 13404 13619 22562 19437 19155>,
			<13190 13574 13840 22710 20124 19196>,
			<13307 13733 14056 22727 20561 19133>,
			<13300 13764 14071 21315 20228 18918>,
			<13220 13777 14066 19643 19478 18527>,
			<13098 13777 14063 19475 19399 18723>,
			<12822 13703 14068 19492 20183 20100>,
			<12491 13597 13983 18521 19975 20183>,
			<12126 13392 13591 17534 18518 18711>,
			<12322 13072 13643 19589 19058 18833>,
			<12356 12846 13773 18088 17800 17782>,
			<12457 12899 13608 18250 18668 17618>,
			<12657 13116 13713 18595 18391 17073>,
			<12967 13181 13956 18380 17938 16728>,
			<13311 13308 14544 18533 17466 16140>,
			<13280 13229 14520 19843 19910 17448>,
			<12823 13100 13735 20268 18112 17379>,
			<11714 13076 13007 20764 20628 20364>,
			<10008 12399 12751 21731 23378 23621>,
			<10008 12399 12751 21731 23378 23621>,
			<10008 12399 12751 21731 23378 23621>;
	};

	qcom,pc-temp-y6-lut {
		qcom,lut-col-legend = <(-10) 0 10 25 40 50>;
		qcom,lut-row-legend = <10000 9800 9600 9400 9200 9000>,
			<8800 8600 8400 8200 8000 7800>,
			<7600 7400 7200 7000 6800 6600>,
			<6400 6200 6000 5800 5600 5400>,
			<5200 5000 4800 4600 4400 4200>,
			<4000 3800 3600 3400 3200 3000>,
			<2800 2600 2400 2200 2000 1800>,
			<1600 1400 1200 1000 900 800>,
			<700 600 500 400 300 200>,
			<100 0>;
		qcom,lut-data = <6518 5800 5357 5070 5011 5004>,
			<6484 5842 5384 5071 5012 5003>,
			<6450 5867 5401 5072 5012 5003>,
			<6414 5882 5412 5073 5013 5003>,
			<6379 5887 5417 5073 5013 5003>,
			<6342 5889 5418 5073 5014 5004>,
			<6304 5875 5412 5073 5015 5004>,
			<6265 5852 5402 5072 5016 5005>,
			<6228 5839 5394 5072 5017 5006>,
			<6188 5831 5388 5073 5018 5007>,
			<6170 5821 5382 5073 5019 5008>,
			<6177 5802 5376 5075 5021 5010>,
			<6187 5784 5371 5077 5023 5011>,
			<6180 5782 5372 5079 5025 5013>,
			<6135 5783 5377 5082 5028 5015>,
			<6086 5784 5379 5085 5031 5017>,
			<6041 5769 5379 5090 5034 5020>,
			<6000 5741 5377 5096 5037 5024>,
			<5975 5716 5371 5104 5043 5028>,
			<5958 5690 5351 5112 5051 5034>,
			<5945 5665 5330 5112 5053 5036>,
			<5934 5640 5307 5094 5040 5026>,
			<5925 5618 5286 5073 5023 5012>,
			<5928 5598 5275 5062 5016 5006>,
			<5946 5579 5268 5054 5011 5002>,
			<5968 5572 5262 5052 5009 5000>,
			<5991 5590 5257 5053 5010 5001>,
			<6018 5622 5252 5053 5011 5002>,
			<6045 5653 5246 5055 5013 5003>,
			<6073 5689 5239 5058 5016 5006>,
			<6102 5727 5238 5060 5020 5009>,
			<6132 5766 5252 5062 5024 5012>,
			<6163 5807 5275 5065 5027 5015>,
			<6192 5846 5298 5067 5027 5016>,
			<6221 5885 5326 5069 5027 5018>,
			<6250 5923 5357 5069 5026 5017>,
			<6278 5960 5391 5066 5021 5010>,
			<6304 5996 5427 5064 5016 5004>,
			<6329 6030 5463 5061 5014 5004>,
			<6352 6061 5501 5060 5014 5004>,
			<6374 6092 5540 5062 5014 5005>,
			<6396 6119 5582 5067 5016 5008>,
			<6423 6147 5630 5068 5016 5007>,
			<6459 6176 5688 5068 5011 5000>,
			<6518 6216 5765 5066 5010 5000>,
			<6565 6233 5766 5070 5016 5009>,
			<6624 6280 5824 5079 5024 5019>,
			<6697 6331 5894 5090 5036 5031>,
			<6789 6390 5971 5104 5048 5043>,
			<6907 6462 6059 5115 5052 5038>,
			<7069 6540 6130 5102 5025 5012>,
			<7394 6656 6223 5099 5023 5014>,
			<8484 6863 6378 5116 5030 5021>,
			<12046 7465 6554 5145 5043 5035>,
			<12046 7465 6554 5145 5043 5035>,
			<12046 7465 6554 5145 5043 5035>;
	};

};
